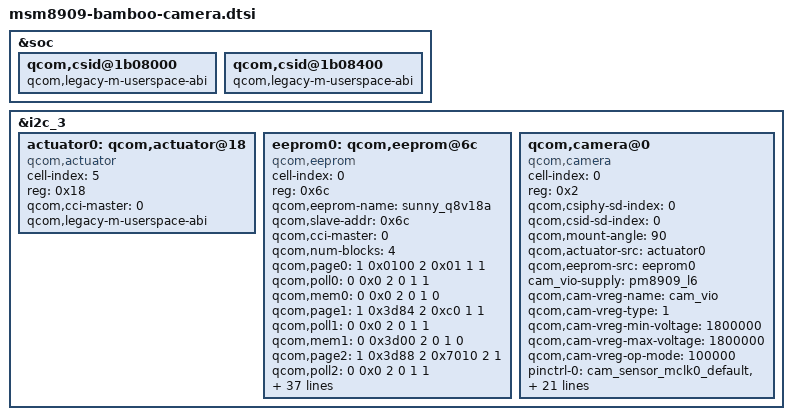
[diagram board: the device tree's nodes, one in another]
/*
 * Copyright (c) 2014-2015, The Linux Foundation. All rights reserved.
 * Copyright (C) 2026 The LineageOS Project
 *
 * This program is free software; you can redistribute it and/or modify
 * it under the terms of the GNU General Public License version 2 and
 * only version 2 as published by the Free Software Foundation.
 *
 * This program is distributed in the hope that it will be useful,
 * but WITHOUT ANY WARRANTY; without even the implied warranty of
 * MERCHANTABILITY or FITNESS FOR A PARTICULAR PURPOSE.  See the
 * GNU General Public License for more details.
 */

&soc {
	qcom,csid@1b08000 {
		qcom,legacy-m-userspace-abi;
	};

	qcom,csid@1b08400 {
		qcom,legacy-m-userspace-abi;
	};
};

&i2c_3 {
	status = "ok";

	actuator0: qcom,actuator@18 {
		cell-index = <5>;
		reg = <0x18>;
		compatible = "qcom,actuator";
		qcom,cci-master = <0>;

		qcom,legacy-m-userspace-abi;
	};

	eeprom0: qcom,eeprom@6c {
		cell-index = <0>;
		reg = <0x6c>;
		qcom,eeprom-name = "sunny_q8v18a";
		compatible = "qcom,eeprom";
		qcom,slave-addr = <0x6c>;
		qcom,cci-master = <0>;
		qcom,num-blocks = <4>;
		qcom,page0 = <1 0x0100 2 0x01 1 1>;
		qcom,poll0 = <0 0x0 2 0 1 1>;
		qcom,mem0 = <0 0x0 2 0 1 0>;
		qcom,page1 = <1 0x3d84 2 0xc0 1 1>;
		qcom,poll1 = <0 0x0 2 0 1 1>;
		qcom,mem1 = <0 0x3d00 2 0 1 0>;
		qcom,page2 = <1 0x3d88 2 0x7010 2 1>;
		qcom,poll2 = <0 0x0 2 0 1 1>;
		qcom,mem2 = <0 0x3d00 2 0 1 0>;
		qcom,page3 = <1 0x3d8a 2 0x7115 2 1>;
		qcom,pageen3 = <1 0x3d81 2 0x01 1 10>;
		qcom,poll3 = <0 0x0 2 0 1 1>;
		qcom,mem3 = <262 0x7010 2 0 1 1>;
		cam_vio-supply = <&pm8909_l6>;
		qcom,cam-vreg-name = "cam_vio";
		qcom,cam-vreg-type = <1>;
		qcom,cam-vreg-min-voltage = <1800000>;
		qcom,cam-vreg-max-voltage = <1800000>;
		qcom,cam-vreg-op-mode = <100000>;
		pinctrl-names = "cam_default", "cam_suspend";
		pinctrl-0 = <&cam_sensor_mclk0_default &cam_sensor_rear_default>;
		pinctrl-1 = <&cam_sensor_mclk0_sleep &cam_sensor_rear_sleep>;
		gpios = <&msm_gpio 26 0>,
			<&msm_gpio 35 0>,
			<&msm_gpio 31 0>,
			<&msm_gpio 32 0>,
			<&msm_gpio 33 0>;
		qcom,gpio-reset = <1>;
		qcom,gpio-vdig = <2>;
		qcom,gpio-vana = <3>;
		qcom,gpio-vaf = <4>;
		qcom,gpio-req-tbl-num = <0 1 2 3 4>;
		qcom,gpio-req-tbl-flags = <1 0 0 0 0>;
		qcom,gpio-req-tbl-label = "CAMIF_MCLK", "CAM_RESET",
					  "CAM_VDIG", "CAM_VANA", "CAM_VAF";
		qcom,cam-power-seq-type = "sensor_vreg", "sensor_gpio",
			"sensor_gpio", "sensor_gpio", "sensor_gpio",
			"sensor_clk";
		qcom,cam-power-seq-val = "cam_vio", "sensor_gpio_vana",
			"sensor_gpio_vdig", "sensor_gpio_vaf",
			"sensor_gpio_reset", "sensor_cam_mclk";
		qcom,cam-power-seq-cfg-val = <1 1 1 1 1 23880000>;
		qcom,cam-power-seq-delay = <5 5 5 5 5 5>;
		status = "ok";
		clocks = <&clock_gcc clk_mclk0_clk_src>,
				<&clock_gcc clk_gcc_camss_mclk0_clk>;
		clock-names = "cam_src_clk", "cam_clk";
		qcom,clock-rates = <24000000 0>;
	};

	qcom,camera@0 {
		cell-index = <0>;
		compatible = "qcom,camera";
		reg = <0x2>;
		qcom,csiphy-sd-index = <0>;
		qcom,csid-sd-index = <0>;

		qcom,mount-angle = <90>;
		qcom,actuator-src = <&actuator0>;
		qcom,eeprom-src = <&eeprom0>;
		cam_vio-supply = <&pm8909_l6>;
		qcom,cam-vreg-name = "cam_vio";
		qcom,cam-vreg-type = <1>;
		qcom,cam-vreg-min-voltage = <1800000>;
		qcom,cam-vreg-max-voltage = <1800000>;
		qcom,cam-vreg-op-mode = <100000>;
		pinctrl-names = "cam_default", "cam_suspend";
		pinctrl-0 = <&cam_sensor_mclk0_default &cam_sensor_rear_default>;
		pinctrl-1 = <&cam_sensor_mclk0_sleep &cam_sensor_rear_sleep>;
		gpios = <&msm_gpio 26 0>,
			<&msm_gpio 35 0>,
			<&msm_gpio 31 0>,
			<&msm_gpio 32 0>,
			<&msm_gpio 33 0>;
		qcom,gpio-reset = <1>;
		qcom,gpio-vdig = <2>;
		qcom,gpio-vana = <3>;
		qcom,gpio-vaf = <4>;
		qcom,gpio-req-tbl-num = <0 1 2 3 4>;
		qcom,gpio-req-tbl-flags = <1 0 0 0 0>;
		qcom,gpio-req-tbl-label = "CAMIF_MCLK", "CAM_RESET",
					  "CAM_VDIG", "CAM_VANA", "CAM_VAF";
		qcom,sensor-position = <0>;
		qcom,sensor-mode = <0>;
		qcom,cci-master = <0>;
		qcom,mclk-23880000;

		qcom,barrel-flip-regs;
		status = "ok";
		clocks = <&clock_gcc clk_mclk0_clk_src>,
				<&clock_gcc clk_gcc_camss_mclk0_clk>;
		clock-names = "cam_src_clk", "cam_clk";
		qcom,clock-rates = <24000000 0>;
	};
};
